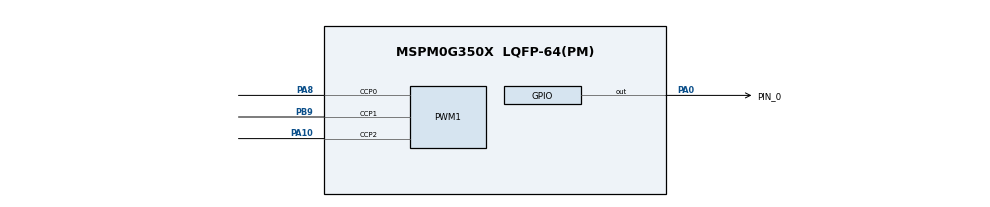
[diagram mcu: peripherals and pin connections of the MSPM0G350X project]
/**
 * @cliArgs --device "MSPM0G350X" --part "Default" --package "LQFP-64(PM)" --product "mspm0_sdk@2.10.00.04"
 * @versions {"tool":"1.26.2+4477"}
 */

/**
 * Import the modules used in this configuration.
 */
const ADC12       = scripting.addModule("/ti/driverlib/ADC12", {}, false);
const ADC121      = ADC12.addInstance();
const ADC122      = ADC12.addInstance();
const GPIO        = scripting.addModule("/ti/driverlib/GPIO", {}, false);
const GPIO1       = GPIO.addInstance();
const PWM         = scripting.addModule("/ti/driverlib/PWM", {}, false);
const PWM1        = PWM.addInstance();
const SYSCTL      = scripting.addModule("/ti/driverlib/SYSCTL");
const TIMERFault  = scripting.addModule("/ti/driverlib/TIMERFault", {}, false);
const TIMERFault1 = TIMERFault.addInstance();

/**
 * Write custom configuration values to the imported modules.
 */
ADC121.$name                      = "ADC12_0";
ADC121.trigSrc                    = "DL_ADC12_TRIG_SRC_EVENT";
ADC121.subChanID                  = 1;
ADC121.samplingOperationMode      = "sequence";
ADC121.endAdd                     = 1;
ADC121.enabledInterrupts          = ["DL_ADC12_INTERRUPT_MEM1_RESULT_LOADED"];
ADC121.repeatMode                 = true;
ADC121.disChan12                  = true;
ADC121.adcMem1chansel             = "DL_ADC12_INPUT_CHAN_1";
ADC121.adcPin0Config.$name        = "ti_driverlib_gpio_GPIOPinGeneric4";
ADC121.peripheral.$assign         = "ADC1";
ADC121.peripheral.adcPin0.$assign = "PA15";
ADC121.peripheral.adcPin1.$assign = "PA16";
ADC121.adcPin1Config.$name        = "ti_driverlib_gpio_GPIOPinGeneric6";

ADC122.$name                      = "ADC12_1";
ADC122.trigSrc                    = "DL_ADC12_TRIG_SRC_EVENT";
ADC122.subChanID                  = 2;
ADC122.samplingOperationMode      = "sequence";
ADC122.repeatMode                 = true;
ADC122.disChan12                  = true;
ADC122.adcMem2chansel             = "DL_ADC12_INPUT_CHAN_6";
ADC122.adcMem1chansel             = "DL_ADC12_INPUT_CHAN_3";
ADC122.adcMem0chansel             = "DL_ADC12_INPUT_CHAN_5";
ADC122.endAdd                     = 1;
ADC122.adcPin5Config.$name        = "ti_driverlib_gpio_GPIOPinGeneric7";
ADC122.peripheral.$assign         = "ADC0";
ADC122.peripheral.adcPin5.$assign = "PB24";
ADC122.peripheral.adcPin3.$assign = "PA24";
ADC122.adcPin3Config.$name        = "ti_driverlib_gpio_GPIOPinGeneric5";

const Board = scripting.addModule("/ti/driverlib/Board", {}, false);

GPIO1.$name                               = "GPIO_GRP_0";
GPIO1.associatedPins[0].$name             = "PIN_0";
GPIO1.associatedPins[0].assignedPort      = "PORTA";
GPIO1.associatedPins[0].launchPadShortcut = "LED1En";
GPIO1.associatedPins[0].subOutputPolicy   = "TOGGLE";
GPIO1.associatedPins[0].pin.$assign       = "PA0";

PWM1.$name                           = "PWM_0";
PWM1.timerCount                      = 133;
PWM1.ccIndexCmpl                     = [0,1];
PWM1.deadBandEn                      = true;
PWM1.dbFallDelayTimerCount           = 3;
PWM1.dbRiseDelayTimerCount           = 3;
PWM1.pwmMode                         = "EDGE_ALIGN_UP";
PWM1.ccIndex                         = [0,1,2];
PWM1.event1PublisherChannel          = 1;
PWM1.event1ControllerInterruptEn     = ["CC2_UP_EVENT"];
PWM1.event2PublisherChannel          = 2;
PWM1.event2ControllerInterruptEn     = ["CC2_UP_EVENT"];
PWM1.faultHandlerEn                  = true;
PWM1.faultConditionDuration          = "FL_LATCH_SW_CLR";
PWM1.faultChannel0BehaviorEntry      = "LOW";
PWM1.faultChannel1BehaviorEntry      = "LOW";
PWM1.faultChannel0BehaviorExit       = "LOW";
PWM1.faultChannel1BehaviorExit       = "LOW";
PWM1.faultTriggerIn                  = "TFIM_ENABLED";
PWM1.faultSource                     = ["0"];
PWM1.faultInputEn                    = "FIEN_ENABLED";
PWM1.faultTimerCountEntry            = "FAULT_ENTRY_CTR_SUSP_COUNT";
PWM1.PWM_CHANNEL_0.$name             = "ti_driverlib_pwm_PWMTimerCC0";
PWM1.PWM_CHANNEL_0.dutyCycle         = 70;
PWM1.PWM_CHANNEL_1.$name             = "ti_driverlib_pwm_PWMTimerCC1";
PWM1.PWM_CHANNEL_1.dutyCycle         = 40;
PWM1.ccp0PinConfig.$name             = "ti_driverlib_gpio_GPIOPinGeneric0";
PWM1.ccp1PinConfig.$name             = "ti_driverlib_gpio_GPIOPinGeneric1";
PWM1.ccp0Pin_cmplConfig.$name        = "ti_driverlib_gpio_GPIOPinGeneric2";
PWM1.ccp1Pin_cmplConfig.$name        = "ti_driverlib_gpio_GPIOPinGeneric3";
PWM1.peripheral.ccp0Pin.$assign      = "PA8";
PWM1.peripheral.ccp0Pin_cmpl.$assign = "PA22";
PWM1.peripheral.ccp1Pin.$assign      = "PB9";
PWM1.peripheral.ccp1Pin_cmpl.$assign = "PA25";
PWM1.peripheral.ccp2Pin.$assign      = "PA10";
PWM1.PWM_CHANNEL_2.$name             = "ti_driverlib_pwm_PWMTimerCC2";
PWM1.ccp2PinConfig.$name             = "ti_driverlib_gpio_GPIOPinGeneric8";

SYSCTL.forceDefaultClkConfig = true;
SYSCTL.HSCLKSource           = "HFCLK";

TIMERFault1.$name                            = "FAULT_0";
PWM1.associatedFault                         = TIMERFault1;
TIMERFault1.enabledFaults                    = ["0"];
TIMERFault1.faultPin0.$assign                = "PB23";
TIMERFault1.faultPin0Config.$name            = "ti_driverlib_gpio_GPIOPinGeneric10";
TIMERFault1.faultPin0Config.enableConfig     = true;
TIMERFault1.faultPin0Config.internalResistor = "PULL_UP";

/**
 * Pinmux solution for unlocked pins/peripherals. This ensures that minor changes to the automatic solver in a future
 * version of the tool will not impact the pinmux you originally saw.  These lines can be completely deleted in order to
 * re-solve from scratch.
 */
Board.peripheral.$suggestSolution          = "DEBUGSS";
Board.peripheral.swclkPin.$suggestSolution = "PA20";
Board.peripheral.swdioPin.$suggestSolution = "PA19";
PWM1.peripheral.$suggestSolution           = "TIMA0";
SYSCTL.peripheral.$suggestSolution         = "SYSCTL";
